# TPTC_FW register map
Vendor: Texas Instruments
Peripheral module from a debugger description file (folder TDA2Px).
Registers are 32-bit, access per field, reset 0x0 unless marked. A register's access mark holds for its fields unless they carry their own. Offsets are as the file gives them; lines under a group give offsets from that group; [hi:lo] are bit positions; {n}, {i} and the like mark numbered series; 'fields as' and 'values as' point back to an identical list; <NAME> marks a mode.

## TPTC_FW
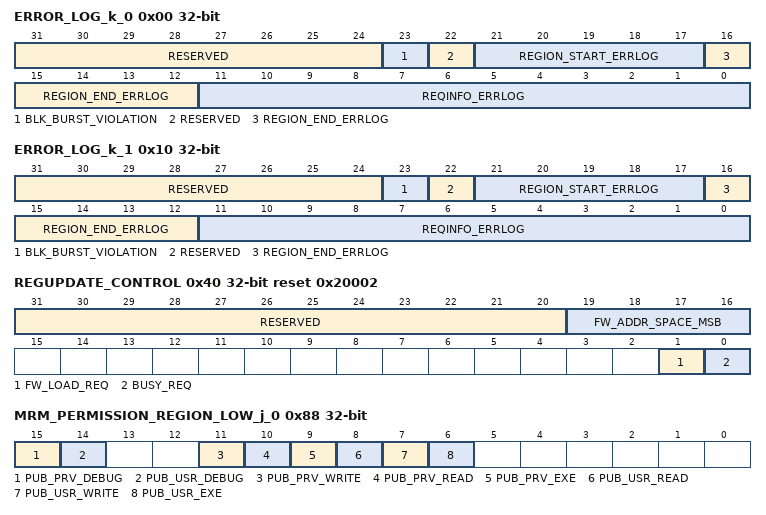
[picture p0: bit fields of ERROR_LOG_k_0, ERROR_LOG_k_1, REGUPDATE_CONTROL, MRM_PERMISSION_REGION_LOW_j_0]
0x00 ERROR_LOG_k_0 — Error log register for port k
  [31:24] RESERVED ro — Reads return 0s.
  [23] BLK_BURST_VIOLATION rw — Read 0x1: 2D burst not allowed or exceeding allowed size Write to clear ERROR_LOG_k and LOGICAL_ADDR_ERRLOG_k registers
  [22] RESERVED ro — Reads return 0s.
  [21:17] REGION_START_ERRLOG rw — Read: Wrong access hit this region number Write to clear ERROR_LOG_k and LOGICAL_ADDR_ERRLOG_k registers
  [16:12] REGION_END_ERRLOG rw — Read: Wrong access hit this region number Write to clear ERROR_LOG_k and LOGICAL_ADDR_ERRLOG_k registers
  [11:0] REQINFO_ERRLOG rw — Read: Error in reqinfo vector mapped as follows: [11: 8] ConnID [3:0] [7] MCMD [0] [6:4] Reserved [3] MReqDebug [2] Reserved [1] MReqSupervisor [0] MReqType Write to clear ERROR_LOG_k and LOGICAL_ADDR_ERRLOG_k registers
0x04 LOGICAL_ADDR_ERRLOG_k_0 ro — Logical Physical Address Error log register for port k
  [31:0] SLVOFS_LOGICAL — Address generated by the Initiator before being translated
0x10 ERROR_LOG_k_1 — Error log register for port k
  fields as ERROR_LOG_k_0
0x14 LOGICAL_ADDR_ERRLOG_k_1 ro — Logical Physical Address Error log register for port k
  fields as LOGICAL_ADDR_ERRLOG_k_0
0x40 REGUPDATE_CONTROL access not given reset 0x20002 — Register update control register
  [31:20] RESERVED ro — Reads return 0s.
  [19:16] FW_ADDR_SPACE_MSB ro — Address space size
  [1] FW_LOAD_REQ — Writing '1' to this bit causes the bit to self-clear and triggers the reload of L3 firewall default values. This bit will subsequently self-set when the reload procedure is complete. Writing '0' has no effect. (access RW W1toClr)
  [0] BUSY_REQ rw — Busy request 0x0: Allow transactions to reach the slave NIU (resume) 0x1: No transaction can reach the slave NIU (suspend)
0x88 MRM_PERMISSION_REGION_LOW_j_0 reset not defined — Region j Permission Low
  [15] PUB_PRV_DEBUG rw — Public Privilege Debug Allowed
  [14] PUB_USR_DEBUG rw — Public User Debug Allowed
  [11] PUB_PRV_WRITE rw — Public Privilege Write Allowed
  [10] PUB_PRV_READ rw — Public Privilege Read Allowed
  [9] PUB_PRV_EXE rw — Public Privilege Exe Allowed
  [8] PUB_USR_READ rw — Public User Read Access Allowed
  [7] PUB_USR_WRITE rw — Public User Write Access Allowed
  [6] PUB_USR_EXE rw — Public User Exe Access Allowed
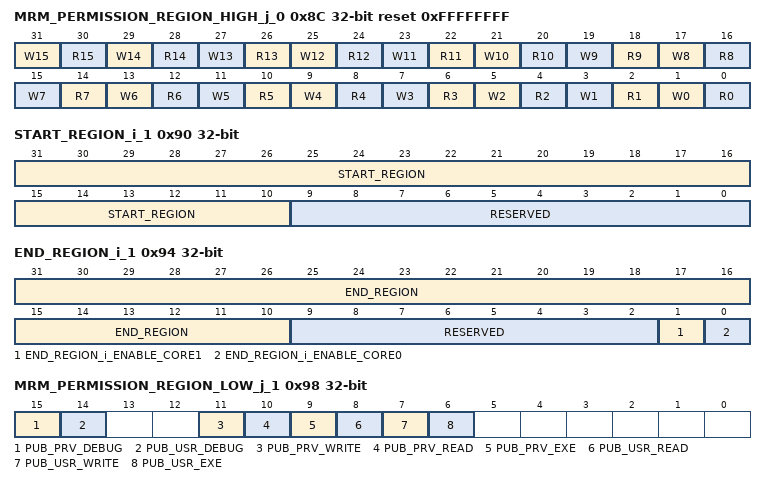
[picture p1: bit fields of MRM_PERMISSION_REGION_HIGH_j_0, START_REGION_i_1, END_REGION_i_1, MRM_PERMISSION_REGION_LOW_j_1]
0x8C MRM_PERMISSION_REGION_HIGH_j_0 rw reset 0xFFFFFFFF — Region j Permission High
  [31] W15 — Master NIU ConnID = 115 write permission
  [30] R15 — Master NIU ConnID = 115 read permission
  [2n+1] W{n} (n=0..14) — Master NIU ConnID = {n} write permission
  [2n] R{n} (n=0..14) — Master NIU ConnID = {n} read permission
0x90 START_REGION_i_1 — Start physical address of region iUpdated L3 firewall description for START_REGION_i and END_REGION_i
  [31:10] START_REGION rw — Physical target start address of firewall region i. The size of this bit field depends on target addressable space, the maximum is [31:10]. See. Each of the LSbits is assumed to be 0.The programmed address is included in the region i boundary.
  [9:0] RESERVED ro — Reads return 0s.
0x94 END_REGION_i_1 — End physical address of region i
  [31:10] END_REGION rw — Physical target end address of firewall region i. The size of this bit field depends on target addressable space, the maximum is [31:10]. See. Each of the LSbits is assumed to be 1.The programmed address is included in the region i boundary.
  [9:2] RESERVED ro — Reads return 0s.
  [1] END_REGION_i_ENABLE_CORE1 rw — Enable this region for port 1.
  [0] END_REGION_i_ENABLE_CORE0 rw — Enable this region for port 0.
0x98 MRM_PERMISSION_REGION_LOW_j_1 reset not defined — Region j Permission Low
  fields as MRM_PERMISSION_REGION_LOW_j_0
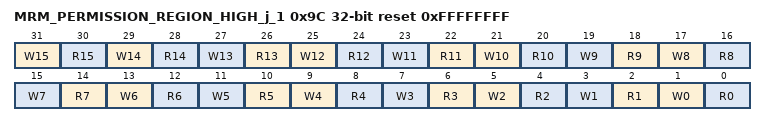
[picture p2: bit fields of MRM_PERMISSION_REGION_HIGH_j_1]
0x9C MRM_PERMISSION_REGION_HIGH_j_1 rw reset 0xFFFFFFFF — Region j Permission High
  fields as MRM_PERMISSION_REGION_HIGH_j_0
